# CY8C5868AXI_LP035 register map
File version: 0.1
CY8C58LP
Registers are 8-bit, read-write, no defined reset value unless marked. A register's access mark holds for its fields unless they carry their own. Offsets are from the block's base; lines under a group give offsets from that group; [hi:lo] are bit positions; {n}, {i} and the like mark numbered series; 'fields as' and 'values as' point back to an identical list; <NAME> marks a mode.

## Memory map
0x00000000 Counter_1
0x00000000 Timer_periode
0x00000000 Detect_Seuil_Recept
0x00000000 US_40kHz
0x00000000 V_seuil
0x00000000 Ampli_Recept
0x00000000 Timer_US
0x40006479 Control_Reg_1

## Counter_1
Base 0x00000000
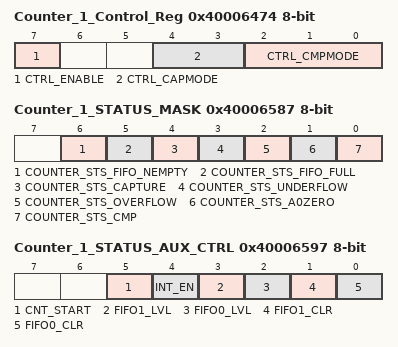
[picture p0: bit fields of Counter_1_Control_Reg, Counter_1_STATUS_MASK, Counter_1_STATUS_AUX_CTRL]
0x40006474 Counter_1_Control_Reg — UDB Control Register - Assigned Control Register Value
  [7] CTRL_ENABLE — Enable Counter
  [4:3] CTRL_CAPMODE — Capture mode
  [2:0] CTRL_CMPMODE — Compare mode
0x40006507 Counter_1_COUNTER — UDB.A0 - Current Counter Value
0x40006527 Counter_1_PERIOD — UDB.D0 - Assigned Period
0x40006537 Counter_1_COMPARE — UDB.D1 - Assigned Compare Value
0x40006587 Counter_1_STATUS_MASK — UDB Status bits Interrupt Mask Enable Register
  [6] COUNTER_STS_FIFO_NEMPTY — FIFO Not Empty Status
  [5] COUNTER_STS_FIFO_FULL — FIFO Full Status
  [4] COUNTER_STS_CAPTURE — Capture Status
  [3] COUNTER_STS_UNDERFLOW — Underflow status
  [2] COUNTER_STS_OVERFLOW — Overflow status
  [1] COUNTER_STS_A0ZERO — A0 Zero ouput status
  [0] COUNTER_STS_CMP — Compare output status
0x40006597 Counter_1_STATUS_AUX_CTRL — UDB Auxilliary Control Register
  [5] CNT_START — FIFO0 clear
    0=E_CNT_START0 (Disable counter); 1=E_CNT_START1 (Enable counter)
  [4] INT_EN
    0=E_INT_EN0 (Interrupt disabled); 1=E_INT_EN1 (Interrupt enabled)
  [3] FIFO1_LVL — FIFO level
    0=E_FIFO_LVL_0 (FIFO LVL: input mode: FIFO not full; output mode: FIFO not empty); 1=E_FIFO_LVL_1 (FIFO LVL: input mode: FIFO at least 1/2 empty; output mode: FIFO at least 1/2 full)
  [2] FIFO0_LVL — FIFO level
    values as FIFO1_LVL
  [1] FIFO1_CLR — FIFO1 clear
    0=E_FIFO_CLR_0 (Normal FIFO operation); 1=E_FIFO_CLR_1 (Clear FIFO state)
  [0] FIFO0_CLR — FIFO0 clear
    values as FIFO1_CLR

## Control_Reg_1
Base 0x40006479
0x00 Control_Reg_1_CONTROL_REG

## Timer_periode
Base 0x00000000
0x40006504 Timer_periode_COUNTER 24-bit — UDB.A0 - Current Down Counter Value
0x40006524 Timer_periode_PERIOD 24-bit — UDB.D0 - Assigned Period
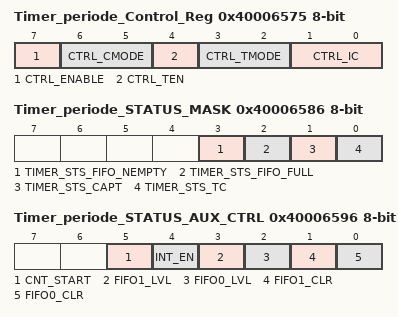
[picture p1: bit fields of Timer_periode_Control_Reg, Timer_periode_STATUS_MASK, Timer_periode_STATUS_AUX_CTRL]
0x40006575 Timer_periode_Control_Reg — UDB Control Register - Assigned Control Register Value
  [7] CTRL_ENABLE — Enable the Timer
  [6:5] CTRL_CMODE — Capture Mode
  [4] CTRL_TEN — Trigger Enable Bit
  [3:2] CTRL_TMODE — Trigger Mode
  [1:0] CTRL_IC — Interrupt Count
0x40006586 Timer_periode_STATUS_MASK — UDB Status bits Interrupt Mask Enable Register
  [3] TIMER_STS_FIFO_NEMPTY ro — FIFO Empty status
  [2] TIMER_STS_FIFO_FULL ro — FIFO Full Status
  [1] TIMER_STS_CAPT ro — Enables the Interrupt on Capture
  [0] TIMER_STS_TC ro — Enables the Interrupt on TC
0x40006596 Timer_periode_STATUS_AUX_CTRL — UDB Auxilliary Control Register
  [5] CNT_START — FIFO0 clear
    0=E_CNT_START0 (Disable counter); 1=E_CNT_START1 (Enable counter)
  [4] INT_EN
    0=E_INT_EN0 (Interrupt disabled); 1=E_INT_EN1 (Interrupt enabled)
  [3] FIFO1_LVL — FIFO level
    0=E_FIFO_LVL_0 (FIFO LVL: input mode: FIFO not full; output mode: FIFO not empty); 1=E_FIFO_LVL_1 (FIFO LVL: input mode: FIFO at least 1/2 empty; output mode: FIFO at least 1/2 full)
  [2] FIFO0_LVL — FIFO level
    values as FIFO1_LVL
  [1] FIFO1_CLR — FIFO1 clear
    0=E_FIFO_CLR_0 (Normal FIFO operation); 1=E_FIFO_CLR_1 (Clear FIFO state)
  [0] FIFO0_CLR — FIFO0 clear
    values as FIFO1_CLR

## US_40kHz
Base 0x00000000
0x40006424 US_40kHz_COMPARE_1 16-bit — UDB.D0 - Assigned Compare1 Value
0x40006434 US_40kHz_COMPARE_2 16-bit — UDB.D1 - Assigned Compare2 Value
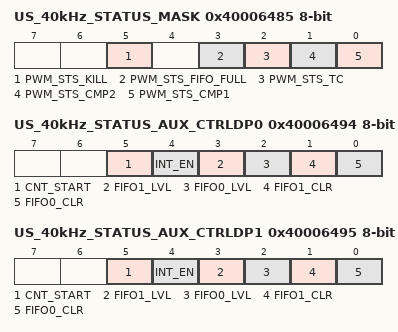
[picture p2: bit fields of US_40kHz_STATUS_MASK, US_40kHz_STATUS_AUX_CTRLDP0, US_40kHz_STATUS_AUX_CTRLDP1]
0x40006485 US_40kHz_STATUS_MASK — UDB Status bits Interrupt Mask Enable Register
  [5] PWM_STS_KILL ro — Enables the Interrupt on Kill
  [3] PWM_STS_FIFO_FULL ro — FIFO Full Status Mask
  [2] PWM_STS_TC ro — Enables the Interrupt on Terminal Count
  [1] PWM_STS_CMP2 ro — Enables the Interrupt on Compare 2
  [0] PWM_STS_CMP1 ro — Enables the Interrupt on Compare 1
0x40006494 US_40kHz_STATUS_AUX_CTRLDP0 — UDB Auxilliary Control Register
  [5] CNT_START — FIFO0 clear
    0=E_CNT_START0 (Disable counter); 1=E_CNT_START1 (Enable counter)
  [4] INT_EN
    0=E_INT_EN0 (Interrupt disabled); 1=E_INT_EN1 (Interrupt enabled)
  [3] FIFO1_LVL — FIFO level
    0=E_FIFO_LVL_0 (FIFO LVL: input mode: FIFO not full; output mode: FIFO not empty); 1=E_FIFO_LVL_1 (FIFO LVL: input mode: FIFO at least 1/2 empty; output mode: FIFO at least 1/2 full)
  [2] FIFO0_LVL — FIFO level
    values as FIFO1_LVL
  [1] FIFO1_CLR — FIFO1 clear
    0=E_FIFO_CLR_0 (Normal FIFO operation); 1=E_FIFO_CLR_1 (Clear FIFO state)
  [0] FIFO0_CLR — FIFO0 clear
    values as FIFO1_CLR
0x40006495 US_40kHz_STATUS_AUX_CTRLDP1 — UDB Auxilliary Control Register
  fields as US_40kHz_STATUS_AUX_CTRLDP0
